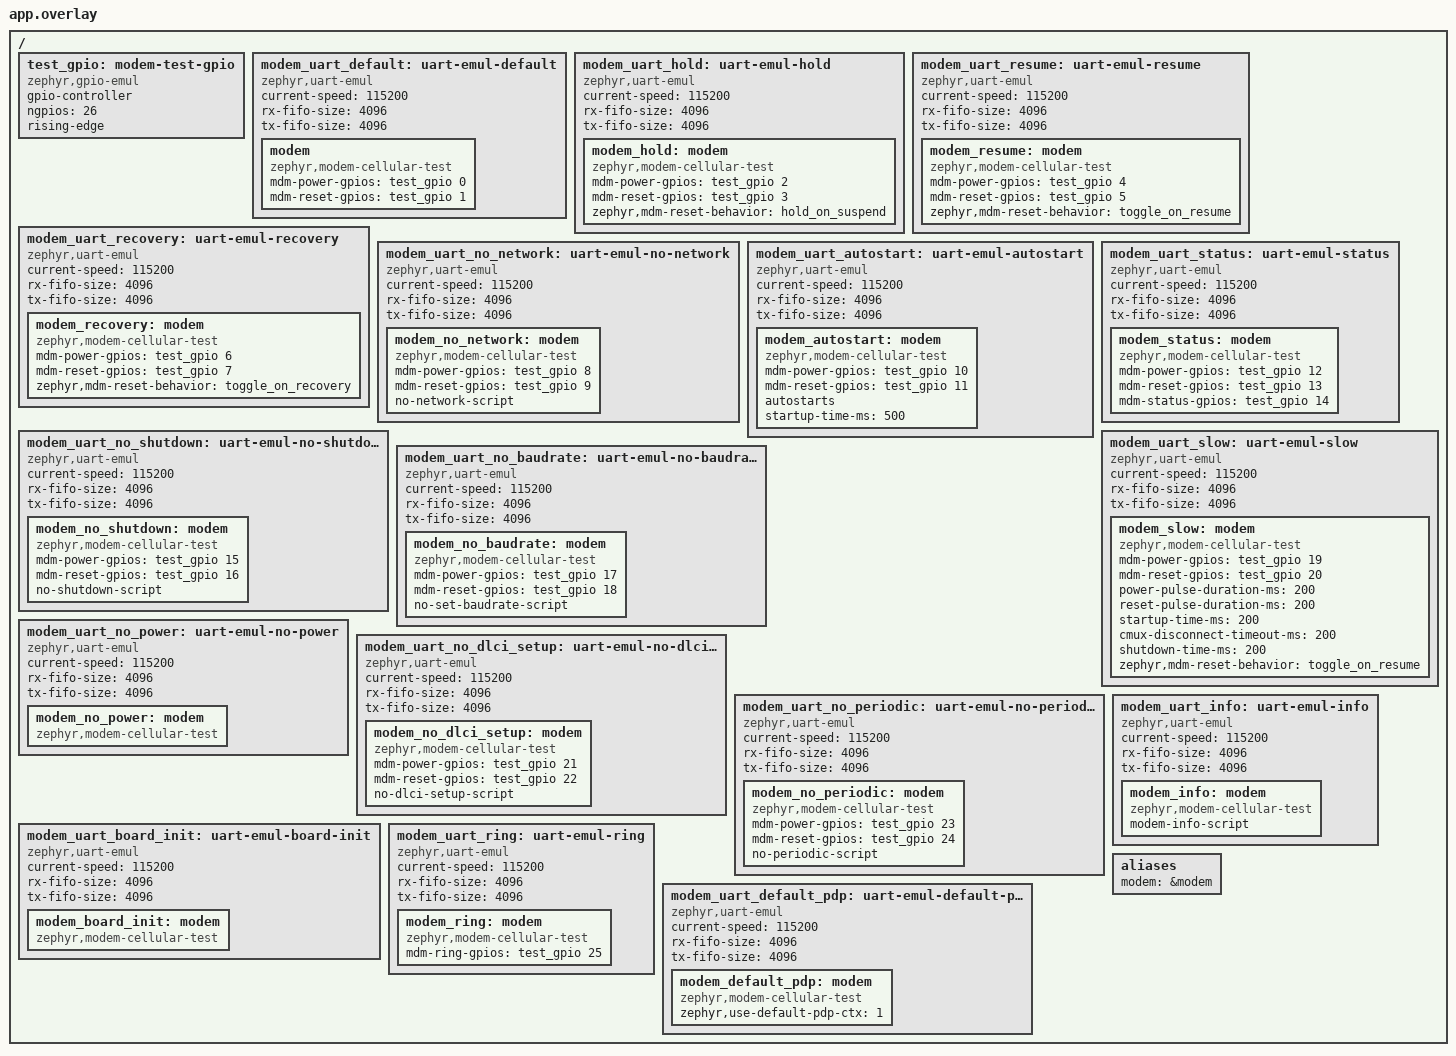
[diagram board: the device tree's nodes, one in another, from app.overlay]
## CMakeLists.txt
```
# Copyright (c) 2026 Embeint Inc
# SPDX-License-Identifier: Apache-2.0

cmake_minimum_required(VERSION 3.28.0)
find_package(Zephyr REQUIRED HINTS $ENV{ZEPHYR_BASE})
project(modem_cellular_state_machine_test)

target_sources(app PRIVATE
  driver/modem_cellular_test.c
  src/common/stubs.c
  src/common/test_helpers.c
)
target_include_directories(app PRIVATE
  driver
  src/common
  ${ZEPHYR_BASE}/subsys/modem
)

# On-demand connect rejects modems with a network script, so it runs on its own devicetree
if(CONFIG_MODEM_CELLULAR_ON_DEMAND_CONNECT)
  target_sources(app PRIVATE
    src/on_demand.c
  )
else()
  target_sources(app PRIVATE
    src/api.c
    src/board_init.c
    src/gpio.c
    src/main.c
    src/modem_info.c
    src/network_status.c
    src/periodic.c
    src/ppp_dead.c
    src/ring.c
    src/script_errors.c
    src/signal.c
    src/suspend.c
    src/unsolicited.c
  )
endif()
```

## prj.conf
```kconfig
# Copyright (c) 2026 Embeint Inc
# SPDX-License-Identifier: Apache-2.0

CONFIG_ZTEST=y

CONFIG_SERIAL=y
CONFIG_EMUL=y
CONFIG_UART_EMUL=y
CONFIG_GPIO=y

CONFIG_MODEM=y
CONFIG_MODEM_MODULES=y
CONFIG_MODEM_CELLULAR=y
CONFIG_MODEM_CELLULAR_HW_DEPENDENCIES=n
CONFIG_MODEM_CHAT=y
CONFIG_MODEM_PIPELINK=y

CONFIG_NETWORKING=y
CONFIG_NET_L2_PPP=y
CONFIG_NET_MGMT=y
CONFIG_NET_MGMT_EVENT=y
CONFIG_PM_DEVICE=y

CONFIG_ETH_NATIVE_TAP=n

CONFIG_LOG=y
CONFIG_LOG_MODE_IMMEDIATE=y
CONFIG_MODEM_LOG_LEVEL_INF=y

CONFIG_MODEM_CELLULAR_APN=""
# Differs from the UARTs' current-speed so baudrate changes are observable
CONFIG_MODEM_CELLULAR_NEW_BAUDRATE=921600
CONFIG_MODEM_CELLULAR_NEW_BAUDRATE_DELAY=1
CONFIG_MODEM_CELLULAR_RESET_POWER_ON_DELAY_MS=100
CONFIG_MODEM_CELLULAR_RECOVERY_BACKOFF_MS=100
CONFIG_MODEM_CELLULAR_MAX_RECOVERIES=3
CONFIG_MODEM_CELLULAR_PERIODIC_SCRIPT_MS=500

CONFIG_MAIN_STACK_SIZE=4096
CONFIG_SYSTEM_WORKQUEUE_STACK_SIZE=4096
CONFIG_ZTEST_STACK_SIZE=4096
```

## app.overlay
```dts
/*
 * Copyright (c) 2026 Embeint Inc
 *
 * SPDX-License-Identifier: Apache-2.0
 */

/ {
	test_gpio: modem-test-gpio {
		compatible = "zephyr,gpio-emul";
		gpio-controller;
		#gpio-cells = <2>;
		ngpios = <26>;
		/* The ring indicator interrupts on its rising edge */
		rising-edge;
		status = "okay";
	};

	modem_uart_default: uart-emul-default {
		compatible = "zephyr,uart-emul";
		current-speed = <115200>;
		rx-fifo-size = <4096>;
		tx-fifo-size = <4096>;
		status = "okay";

		modem: modem {
			compatible = "zephyr,modem-cellular-test";
			mdm-power-gpios = <&test_gpio 0 0>;
			mdm-reset-gpios = <&test_gpio 1 0>;
			status = "okay";
		};
	};

	modem_uart_hold: uart-emul-hold {
		compatible = "zephyr,uart-emul";
		current-speed = <115200>;
		rx-fifo-size = <4096>;
		tx-fifo-size = <4096>;
		status = "okay";

		modem_hold: modem {
			compatible = "zephyr,modem-cellular-test";
			mdm-power-gpios = <&test_gpio 2 0>;
			mdm-reset-gpios = <&test_gpio 3 0>;
			zephyr,mdm-reset-behavior = "hold_on_suspend";
			status = "okay";
		};
	};

	modem_uart_resume: uart-emul-resume {
		compatible = "zephyr,uart-emul";
		current-speed = <115200>;
		rx-fifo-size = <4096>;
		tx-fifo-size = <4096>;
		status = "okay";

		modem_resume: modem {
			compatible = "zephyr,modem-cellular-test";
			mdm-power-gpios = <&test_gpio 4 0>;
			mdm-reset-gpios = <&test_gpio 5 0>;
			zephyr,mdm-reset-behavior = "toggle_on_resume";
			status = "okay";
		};
	};

	modem_uart_recovery: uart-emul-recovery {
		compatible = "zephyr,uart-emul";
		current-speed = <115200>;
		rx-fifo-size = <4096>;
		tx-fifo-size = <4096>;
		status = "okay";

		modem_recovery: modem {
			compatible = "zephyr,modem-cellular-test";
			mdm-power-gpios = <&test_gpio 6 0>;
			mdm-reset-gpios = <&test_gpio 7 0>;
			zephyr,mdm-reset-behavior = "toggle_on_recovery";
			status = "okay";
		};
	};

	modem_uart_no_network: uart-emul-no-network {
		compatible = "zephyr,uart-emul";
		current-speed = <115200>;
		rx-fifo-size = <4096>;
		tx-fifo-size = <4096>;
		status = "okay";

		modem_no_network: modem {
			compatible = "zephyr,modem-cellular-test";
			mdm-power-gpios = <&test_gpio 8 0>;
			mdm-reset-gpios = <&test_gpio 9 0>;
			no-network-script;
			status = "okay";
		};
	};

	modem_uart_autostart: uart-emul-autostart {
		compatible = "zephyr,uart-emul";
		current-speed = <115200>;
		rx-fifo-size = <4096>;
		tx-fifo-size = <4096>;
		status = "okay";

		modem_autostart: modem {
			compatible = "zephyr,modem-cellular-test";
			mdm-power-gpios = <&test_gpio 10 0>;
			mdm-reset-gpios = <&test_gpio 11 0>;
			autostarts;
			startup-time-ms = <500>;
			status = "okay";
		};
	};

	modem_uart_status: uart-emul-status {
		compatible = "zephyr,uart-emul";
		current-speed = <115200>;
		rx-fifo-size = <4096>;
		tx-fifo-size = <4096>;
		status = "okay";

		modem_status: modem {
			compatible = "zephyr,modem-cellular-test";
			mdm-power-gpios = <&test_gpio 12 0>;
			mdm-reset-gpios = <&test_gpio 13 0>;
			mdm-status-gpios = <&test_gpio 14 0>;
			status = "okay";
		};
	};

	modem_uart_no_shutdown: uart-emul-no-shutdown {
		compatible = "zephyr,uart-emul";
		current-speed = <115200>;
		rx-fifo-size = <4096>;
		tx-fifo-size = <4096>;
		status = "okay";

		modem_no_shutdown: modem {
			compatible = "zephyr,modem-cellular-test";
			mdm-power-gpios = <&test_gpio 15 0>;
			mdm-reset-gpios = <&test_gpio 16 0>;
			no-shutdown-script;
			status = "okay";
		};
	};

	modem_uart_no_baudrate: uart-emul-no-baudrate {
		compatible = "zephyr,uart-emul";
		current-speed = <115200>;
		rx-fifo-size = <4096>;
		tx-fifo-size = <4096>;
		status = "okay";

		modem_no_baudrate: modem {
			compatible = "zephyr,modem-cellular-test";
			mdm-power-gpios = <&test_gpio 17 0>;
			mdm-reset-gpios = <&test_gpio 18 0>;
			no-set-baudrate-script;
			status = "okay";
		};
	};

	modem_uart_slow: uart-emul-slow {
		compatible = "zephyr,uart-emul";
		current-speed = <115200>;
		rx-fifo-size = <4096>;
		tx-fifo-size = <4096>;
		status = "okay";

		/* Every timed state lasts long enough for a test to act within it */
		modem_slow: modem {
			compatible = "zephyr,modem-cellular-test";
			mdm-power-gpios = <&test_gpio 19 0>;
			mdm-reset-gpios = <&test_gpio 20 0>;
			power-pulse-duration-ms = <200>;
			reset-pulse-duration-ms = <200>;
			startup-time-ms = <200>;
			cmux-disconnect-timeout-ms = <200>;
			shutdown-time-ms = <200>;
			zephyr,mdm-reset-behavior = "toggle_on_resume";
			status = "okay";
		};
	};

	modem_uart_no_power: uart-emul-no-power {
		compatible = "zephyr,uart-emul";
		current-speed = <115200>;
		rx-fifo-size = <4096>;
		tx-fifo-size = <4096>;
		status = "okay";

		modem_no_power: modem {
			compatible = "zephyr,modem-cellular-test";
			status = "okay";
		};
	};

	modem_uart_no_dlci_setup: uart-emul-no-dlci-setup {
		compatible = "zephyr,uart-emul";
		current-speed = <115200>;
		rx-fifo-size = <4096>;
		tx-fifo-size = <4096>;
		status = "okay";

		modem_no_dlci_setup: modem {
			compatible = "zephyr,modem-cellular-test";
			mdm-power-gpios = <&test_gpio 21 0>;
			mdm-reset-gpios = <&test_gpio 22 0>;
			no-dlci-setup-script;
			status = "okay";
		};
	};

	modem_uart_no_periodic: uart-emul-no-periodic {
		compatible = "zephyr,uart-emul";
		current-speed = <115200>;
		rx-fifo-size = <4096>;
		tx-fifo-size = <4096>;
		status = "okay";

		modem_no_periodic: modem {
			compatible = "zephyr,modem-cellular-test";
			mdm-power-gpios = <&test_gpio 23 0>;
			mdm-reset-gpios = <&test_gpio 24 0>;
			no-periodic-script;
			status = "okay";
		};
	};

	modem_uart_info: uart-emul-info {
		compatible = "zephyr,uart-emul";
		current-speed = <115200>;
		rx-fifo-size = <4096>;
		tx-fifo-size = <4096>;
		status = "okay";

		modem_info: modem {
			compatible = "zephyr,modem-cellular-test";
			modem-info-script;
			status = "okay";
		};
	};

	modem_uart_board_init: uart-emul-board-init {
		compatible = "zephyr,uart-emul";
		current-speed = <115200>;
		rx-fifo-size = <4096>;
		tx-fifo-size = <4096>;
		status = "okay";

		/* The only instance with a board init script */
		modem_board_init: modem {
			compatible = "zephyr,modem-cellular-test";
			status = "okay";
		};
	};

	modem_uart_ring: uart-emul-ring {
		compatible = "zephyr,uart-emul";
		current-speed = <115200>;
		rx-fifo-size = <4096>;
		tx-fifo-size = <4096>;
		status = "okay";

		modem_ring: modem {
			compatible = "zephyr,modem-cellular-test";
			mdm-ring-gpios = <&test_gpio 25 0>;
			status = "okay";
		};
	};

	modem_uart_default_pdp: uart-emul-default-pdp {
		compatible = "zephyr,uart-emul";
		current-speed = <115200>;
		rx-fifo-size = <4096>;
		tx-fifo-size = <4096>;
		status = "okay";

		/* The modem activates the default context (cid 0) itself, no APN is configured */
		modem_default_pdp: modem {
			compatible = "zephyr,modem-cellular-test";
			zephyr,use-default-pdp-ctx = <1>;
			status = "okay";
		};
	};

	aliases {
		modem = &modem;
	};
};
```

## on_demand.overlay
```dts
/*
 * Copyright (c) 2026 Embeint Inc
 *
 * SPDX-License-Identifier: Apache-2.0
 */

/ {
	test_gpio: modem-test-gpio {
		compatible = "zephyr,gpio-emul";
		gpio-controller;
		#gpio-cells = <2>;
		ngpios = <3>;
		/* The ring indicator interrupts on its rising edge */
		rising-edge;
		status = "okay";
	};

	modem_uart_on_demand: uart-emul-on-demand {
		compatible = "zephyr,uart-emul";
		current-speed = <115200>;
		rx-fifo-size = <4096>;
		tx-fifo-size = <4096>;
		status = "okay";

		/* On-demand connect requires a modem without a network script */
		modem_on_demand: modem {
			compatible = "zephyr,modem-cellular-test";
			mdm-power-gpios = <&test_gpio 0 0>;
			mdm-reset-gpios = <&test_gpio 1 0>;
			mdm-ring-gpios = <&test_gpio 2 0>;
			no-network-script;
			status = "okay";
		};
	};
};
```

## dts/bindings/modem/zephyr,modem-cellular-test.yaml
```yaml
# Copyright (c) 2026 Embeint Inc
# SPDX-License-Identifier: Apache-2.0

description: Zephyr test cellular modem

compatible: "zephyr,modem-cellular-test"

include: zephyr,cellular-modem-device.yaml

properties:
  no-set-baudrate-script:
    type: boolean
    description: Omit the optional UART baud-rate configuration script

  no-network-script:
    type: boolean
    description: Omit the optional network registration script

  no-periodic-script:
    type: boolean
    description: Omit the optional periodic status script

  no-shutdown-script:
    type: boolean
    description: Omit the optional modem shutdown script

  no-dlci-setup-script:
    type: boolean
    description: Omit the optional DLCI setup script

  modem-info-script:
    type: boolean
    description: Query every modem info string as part of the init script

  startup-time-ms:
    type: int
    default: 1
    description: Time to wait for the modem ready indication after power on

  power-pulse-duration-ms:
    type: int
    default: 1
    description: Duration of the power key pulse

  reset-pulse-duration-ms:
    type: int
    default: 1
    description: Duration of the reset pulse

  cmux-disconnect-timeout-ms:
    type: int
    default: 1
    description: Time to wait for the modem to return to AT mode after CMUX disconnects

  shutdown-time-ms:
    type: int
    default: 1
    description: Time to wait for the modem to power off
```

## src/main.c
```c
/*
 * Copyright (c) 2026 Embeint Inc
 *
 * SPDX-License-Identifier: Apache-2.0
 */

#include "test_helpers.h"

#include <zephyr/device.h>
#include <zephyr/drivers/modem/modem_cellular.h>
#include <modem_cellular_test.h>
#include <zephyr/modem/pipe.h>
#include <zephyr/modem/pipelink.h>
#include <zephyr/ztest.h>

#include <string.h>

BUILD_ASSERT(IS_ENABLED(CONFIG_MODEM_CHAT));
BUILD_ASSERT(IS_ENABLED(CONFIG_MODEM_PIPELINK));
BUILD_ASSERT(!IS_ENABLED(CONFIG_MODEM_CMUX));
BUILD_ASSERT(!IS_ENABLED(CONFIG_MODEM_PPP));
BUILD_ASSERT(!IS_ENABLED(CONFIG_MODEM_BACKEND_UART));

static const struct device *const modem = DEVICE_DT_GET(DT_ALIAS(modem));
static const struct device *const modem_no_network = DEVICE_DT_GET(DT_NODELABEL(modem_no_network));
static const struct device *const modem_no_baudrate =
	DEVICE_DT_GET(DT_NODELABEL(modem_no_baudrate));
static const struct device *const modem_no_dlci_setup =
	DEVICE_DT_GET(DT_NODELABEL(modem_no_dlci_setup));

MODEM_PIPELINK_DT_DECLARE(DT_ALIAS(modem), user_pipe_0);
MODEM_PIPELINK_DT_DECLARE(DT_ALIAS(modem), user_pipe_1);

/* Answer the first periodic script and check the driver stays registered */
static void run_periodic_script(const struct device *dev)
{
	expect_line(TEST_BACKEND_PIPE_DLCI1, MODEM_CELLULAR_TEST_PERIODIC_CMD);
	ok(TEST_BACKEND_PIPE_DLCI1);
	expect_state(dev, TEST_BACKEND_STATE_LINK_UP);
}

ZTEST(modem_cellular_state_machine, test_boot_with_network_script)
{
	modem_restart(modem);
	advance_to(modem, BOOT_LINK_UP);
	zassert_equal(CONFIG_MODEM_CELLULAR_NEW_BAUDRATE, uart_baudrate(modem),
		      "UART baudrate was not switched");

	run_periodic_script(modem);
	suspend_and_shutdown(modem);

	/* The modem powers up at its default baudrate, so the UART must be restored first */
	zassert_ok(modem_cellular_pm_action(modem, PM_DEVICE_ACTION_RESUME), "resume failed");
	expect_line(TEST_BACKEND_PIPE_UART, MODEM_CELLULAR_TEST_SET_BAUDRATE_CMD);
	zassert_equal(modem_power_up_baudrate(modem), uart_baudrate(modem),
		      "UART baudrate was not restored on power up");
	ok(TEST_BACKEND_PIPE_UART);

	expect_line(TEST_BACKEND_PIPE_UART, MODEM_CELLULAR_TEST_INIT_CMD);
	zassert_equal(CONFIG_MODEM_CELLULAR_NEW_BAUDRATE, uart_baudrate(modem),
		      "UART baudrate was not switched");
}

ZTEST(modem_cellular_state_machine, test_boot_without_network_script)
{
	modem_restart(modem_no_network);

	/* Dials straight after the APN script, then waits for registration */
	advance_to(modem_no_network, BOOT_LINK_UP);
	run_periodic_script(modem_no_network);
	suspend_and_shutdown(modem_no_network);
}

ZTEST(modem_cellular_state_machine, test_boot_without_set_baudrate_script)
{
	const uint32_t original = uart_baudrate(modem_no_baudrate);

	modem_restart(modem_no_baudrate);

	/* Boot goes straight to the init script and leaves the UART untouched */
	advance_to(modem_no_baudrate, BOOT_LINK_UP);
	zassert_equal(original, uart_baudrate(modem_no_baudrate), "UART baudrate changed");

	run_periodic_script(modem_no_baudrate);
	suspend_and_shutdown(modem_no_baudrate);
	zassert_equal(original, uart_baudrate(modem_no_baudrate), "UART baudrate changed");
}

ZTEST(modem_cellular_state_machine, test_boot_without_dlci_setup_script)
{
	modem_restart(modem_no_dlci_setup);

	/* The APN command is the first line once the CMUX is up */
	advance_to(modem_no_dlci_setup, BOOT_LINK_UP);
	run_periodic_script(modem_no_dlci_setup);
	suspend_and_shutdown(modem_no_dlci_setup);
}

/* PPP may never report the link dead, so losing registration must not park the driver */
ZTEST(modem_cellular_state_machine, test_deregistration_without_ppp_dead)
{
	modem_restart(modem);
	advance_to(modem, BOOT_DEREGISTERED);

	/* PPP is released once the wait for it times out */
	expect_state(modem, TEST_BACKEND_STATE_CMUX);
	registered(TEST_BACKEND_PIPE_DLCI1);
	expect_line(TEST_BACKEND_PIPE_DLCI2, MODEM_CELLULAR_TEST_DIAL_CMD);
	ok(TEST_BACKEND_PIPE_DLCI2);
	expect_state(modem, TEST_BACKEND_STATE_LINK_UP);
}

/* User pipes are connected while the CMUX is up, each carrying its own DLCI */
ZTEST(modem_cellular_state_machine, test_user_pipes)
{
	static const char cmd[] = "AT+USER\r";
	const struct {
		struct modem_pipelink *link;
		enum test_backend_pipe_id pipe;
	} user_pipes[] = {
		{MODEM_PIPELINK_DT_GET(DT_ALIAS(modem), user_pipe_0), TEST_BACKEND_PIPE_USER3},
		{MODEM_PIPELINK_DT_GET(DT_ALIAS(modem), user_pipe_1), TEST_BACKEND_PIPE_USER4},
	};

	modem_restart(modem);
	advance_to(modem, BOOT_CMUX_PENDING);
	for (size_t i = 0; i < ARRAY_SIZE(user_pipes); i++) {
		zassert_false(modem_pipelink_is_connected(user_pipes[i].link),
			      "user pipe %zu connected before the CMUX", i);
	}

	test_backend_cmux_connect_finish(true);
	expect_line(TEST_BACKEND_PIPE_DLCI1, MODEM_CELLULAR_TEST_DLCI_SETUP_CMD);
	for (size_t i = 0; i < ARRAY_SIZE(user_pipes); i++) {
		struct modem_pipe *pipe = modem_pipelink_get_pipe(user_pipes[i].link);

		zassert_true(modem_pipelink_is_connected(user_pipes[i].link),
			     "user pipe %zu not connected", i);
		zassert_ok(modem_pipe_open(pipe, K_SECONDS(2)));
		zassert_true(test_backend_pipe_is_open(user_pipes[i].pipe));
		zassert_equal(strlen(cmd),
			      modem_pipe_transmit(pipe, (const uint8_t *)cmd, strlen(cmd)));
		expect_line(user_pipes[i].pipe, "AT+USER");
	}

	ok(TEST_BACKEND_PIPE_DLCI1);
	suspend_and_shutdown(modem);
	for (size_t i = 0; i < ARRAY_SIZE(user_pipes); i++) {
		zassert_false(modem_pipelink_is_connected(user_pipes[i].link),
			      "user pipe %zu still connected after suspend", i);
	}
}

/* Halting the driver disconnects the user pipes, as the idle state does */
ZTEST(modem_cellular_state_machine, test_user_pipes_halt)
{
	struct modem_pipelink *const links[] = {
		MODEM_PIPELINK_DT_GET(DT_ALIAS(modem), user_pipe_0),
		MODEM_PIPELINK_DT_GET(DT_ALIAS(modem), user_pipe_1),
	};

	modem_restart(modem);
	advance_to(modem, BOOT_DLCI1_SETUP);
	for (size_t i = 0; i < ARRAY_SIZE(links); i++) {
		zassert_true(modem_pipelink_is_connected(links[i]), "user pipe %zu not connected",
			     i);
	}

	modem_cellular_ztest_halt(modem);
	for (size_t i = 0; i < ARRAY_SIZE(links); i++) {
		zassert_false(modem_pipelink_is_connected(links[i]),
			      "user pipe %zu still connected after halt", i);
	}
}

ZTEST_SUITE(modem_cellular_state_machine, NULL, modem_test_setup, modem_test_before,
	    modem_test_after, NULL);
```

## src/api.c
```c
/*
 * Copyright (c) 2026 Embeint Inc
 *
 * SPDX-License-Identifier: Apache-2.0
 */

#include "test_helpers.h"

#include <zephyr/device.h>
#include <zephyr/drivers/cellular.h>
#include <zephyr/drivers/modem/modem_cellular.h>
#include <zephyr/ztest.h>

#include <stdio.h>
#include <string.h>

static const struct device *const modem = DEVICE_DT_GET(DT_ALIAS(modem));

/* Out of range for each enumeration */
#define INVALID_SIGNAL_TYPE ((enum cellular_signal_type)99)
#define INVALID_INFO_TYPE   ((enum cellular_modem_info_type)99)
#define INVALID_ACCESS_TECH ((enum cellular_access_technology)99)

/* An unknown signal type is rejected without querying the modem */
ZTEST(modem_cellular_api, test_get_signal)
{
	int16_t value = 0;

	modem_restart(modem);
	advance_to(modem, BOOT_LINK_UP);

	zassert_equal(-ENOTSUP, cellular_get_signal(modem, INVALID_SIGNAL_TYPE, &value));
	zassert_equal(0, value, "value written");
	expect_no_line(K_MSEC(100));
}

ZTEST(modem_cellular_api, test_get_modem_info)
{
	char buf[MODEM_CELLULAR_DATA_IMEI_LEN];

	modem_restart(modem);
	advance_to(modem, BOOT_LINK_UP);

	zassert_equal(-ENODATA, cellular_get_modem_info(modem, INVALID_INFO_TYPE, buf,
							 sizeof(buf)));
	zassert_equal(-EINVAL, cellular_get_modem_info(modem, CELLULAR_MODEM_INFO_IMEI, buf, 0));
	zassert_equal(-EINVAL, cellular_get_modem_info(modem, CELLULAR_MODEM_INFO_IMEI, buf, 1));
}

ZTEST(modem_cellular_api, test_get_registration_status)
{
	enum cellular_registration_status status;

	modem_restart(modem);
	advance_to(modem, BOOT_LINK_UP);

	zassert_equal(-ENODATA, cellular_get_registration_status(
					modem, CELLULAR_ACCESS_TECHNOLOGY_UNKNOWN, &status));
	zassert_equal(-ENODATA, cellular_get_registration_status(modem, INVALID_ACCESS_TECH,
								  &status));
}

/* Missing, empty and oversized APNs are rejected and leave the driver waiting for one */
ZTEST(modem_cellular_api, test_set_apn_invalid)
{
	/* One character more than the driver stores, with its terminator */
	char apn[MODEM_CELLULAR_DATA_APN_LEN + 1];
	char cmd[sizeof(apn) + 32];

	modem_restart(modem);
	advance_to(modem, BOOT_AWAIT_APN);

	memset(apn, 'a', MODEM_CELLULAR_DATA_APN_LEN);
	apn[MODEM_CELLULAR_DATA_APN_LEN] = '\0';
	zassert_equal(-EINVAL, cellular_set_apn(modem, NULL));
	zassert_equal(-EINVAL, cellular_set_apn(modem, ""));
	zassert_equal(-EINVAL, cellular_set_apn(modem, apn), "APN of %zu accepted", strlen(apn));
	expect_no_line(K_MSEC(100));

	/* The longest that fits is configured */
	apn[MODEM_CELLULAR_DATA_APN_LEN - 1] = '\0';
	zassert_ok(cellular_set_apn(modem, apn));
	snprintf(cmd, sizeof(cmd), "AT+CGDCONT=1,\"IP\",\"%s\"", apn);
	expect_line(TEST_BACKEND_PIPE_DLCI1, cmd);
}

/* Once configured, the APN cannot be set again or changed while connected */
ZTEST(modem_cellular_api, test_set_apn_configured)
{
	modem_restart(modem);
	advance_to(modem, BOOT_LINK_UP);

	zassert_equal(-EALREADY, cellular_set_apn(modem, TEST_APN));
	zassert_equal(-EBUSY, cellular_set_apn(modem, "other"));
	expect_no_line(K_MSEC(100));
}

ZTEST_SUITE(modem_cellular_api, NULL, modem_test_setup, modem_test_before, modem_test_after, NULL);
```

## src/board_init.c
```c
/*
 * Copyright (c) 2026 Embeint Inc
 *
 * SPDX-License-Identifier: Apache-2.0
 */

#include "test_helpers.h"

#include <zephyr/device.h>
#include <zephyr/drivers/cellular.h>
#include <zephyr/drivers/modem/modem_cellular.h>
#include <modem_cellular_test.h>
#include <zephyr/modem/chat.h>
#include <zephyr/ztest.h>

#define BOARD_INIT_CMD_1 "AT+BOARDINIT=1"
#define BOARD_INIT_CMD_2 "AT+BOARDINIT=2"

static const struct device *const modem_board_init =
	DEVICE_DT_GET(DT_NODELABEL(modem_board_init));

MODEM_CHAT_MATCH_DEFINE(board_init_ok_match, "OK", "", NULL);
MODEM_CHAT_MATCHES_DEFINE(board_init_abort_matches, MODEM_CHAT_MATCH("ERROR", "", NULL));
MODEM_CHAT_SCRIPT_CMDS_DEFINE(board_init_cmds,
			      MODEM_CHAT_SCRIPT_CMD_RESP(BOARD_INIT_CMD_1, board_init_ok_match),
			      MODEM_CHAT_SCRIPT_CMD_RESP(BOARD_INIT_CMD_2, board_init_ok_match));
/* The driver replaces the callback with its own */
MODEM_CHAT_SCRIPT_DEFINE(board_init_script, board_init_cmds, board_init_abort_matches, NULL, 1);

MODEM_CELLULAR_BOARD_INIT_DEFINE(DT_NODELABEL(modem_board_init), &board_init_script);

/* Boot until the board init script is about to start, after the DLCI setup */
static void boot_to_board_init(void)
{
	modem_restart(modem_board_init);
	advance_to(modem_board_init, BOOT_DLCI2_SETUP);
	ok(TEST_BACKEND_PIPE_DLCI2);
}

/* Answer the whole board init script */
static void run_board_init(void)
{
	expect_line(TEST_BACKEND_PIPE_DLCI1, BOARD_INIT_CMD_1);
	ok(TEST_BACKEND_PIPE_DLCI1);
	expect_line(TEST_BACKEND_PIPE_DLCI1, BOARD_INIT_CMD_2);
	ok(TEST_BACKEND_PIPE_DLCI1);
}

/* With the script done, the driver moves on to the APN */
static void expect_apn(void)
{
	expect_read(TEST_BACKEND_PIPE_DLCI1);
	expect_no_line(K_MSEC(100));
	zassert_ok(cellular_set_apn(modem_board_init, TEST_APN));
	expect_line(TEST_BACKEND_PIPE_DLCI1, TEST_APN_CMD);
}

/* The script runs on DLCI1 once the DLCI setup is done, before the APN is configured */
ZTEST(modem_cellular_board_init, test_runs_before_apn)
{
	boot_to_board_init();
	run_board_init();
	expect_apn();
}

/* A failed script is run again from the start after the periodic interval */
ZTEST(modem_cellular_board_init, test_retried)
{
	int64_t start;

	boot_to_board_init();
	expect_line(TEST_BACKEND_PIPE_DLCI1, BOARD_INIT_CMD_1);
	ok(TEST_BACKEND_PIPE_DLCI1);
	expect_line(TEST_BACKEND_PIPE_DLCI1, BOARD_INIT_CMD_2);

	start = k_uptime_get();
	respond_error(TEST_BACKEND_PIPE_DLCI1);
	expect_no_line(K_MSEC(CONFIG_MODEM_CELLULAR_PERIODIC_SCRIPT_MS / 2));
	run_board_init();
	zassert_true(k_uptime_delta(&start) >= CONFIG_MODEM_CELLULAR_PERIODIC_SCRIPT_MS,
		     "retried before the periodic interval");
	expect_apn();
}

/* Spending the failure budget powers the modem down */
ZTEST(modem_cellular_board_init, test_failures_shut_down)
{
	boot_to_board_init();
	for (int i = 0; i < CONFIG_MODEM_CELLULAR_MAX_SCRIPT_FAILURES; i++) {
		expect_line(TEST_BACKEND_PIPE_DLCI1, BOARD_INIT_CMD_1);
		respond_error(TEST_BACKEND_PIPE_DLCI1);
	}

	expect_line(TEST_BACKEND_PIPE_UART, MODEM_CELLULAR_TEST_SHUTDOWN_CMD);
	ok(TEST_BACKEND_PIPE_UART);
	expect_state(modem_board_init, TEST_BACKEND_STATE_OFF);
	expect_no_line(K_MSEC(CONFIG_MODEM_CELLULAR_PERIODIC_SCRIPT_MS * 2));
}

ZTEST(modem_cellular_board_init, test_suspend)
{
	boot_to_board_init();
	expect_line(TEST_BACKEND_PIPE_DLCI1, BOARD_INIT_CMD_1);
	suspend_and_shutdown(modem_board_init);
}

ZTEST_SUITE(modem_cellular_board_init, NULL, modem_test_setup, modem_test_before,
	    modem_test_after, NULL);
```

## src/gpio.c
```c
/*
 * Copyright (c) 2026 Embeint Inc
 *
 * SPDX-License-Identifier: Apache-2.0
 */

#include "test_helpers.h"

#include <zephyr/device.h>
#include <zephyr/drivers/gpio/gpio_emul.h>
#include <zephyr/drivers/modem/modem_cellular.h>
#include <modem_cellular_test.h>
#include <zephyr/ztest.h>

#define AUTOSTART_STARTUP_TIME_MS DT_PROP(DT_NODELABEL(modem_autostart), startup_time_ms)

static const struct device *const modem = DEVICE_DT_GET(DT_ALIAS(modem));
static const struct device *const modem_hold = DEVICE_DT_GET(DT_NODELABEL(modem_hold));
static const struct device *const modem_resume = DEVICE_DT_GET(DT_NODELABEL(modem_resume));
static const struct device *const modem_recovery = DEVICE_DT_GET(DT_NODELABEL(modem_recovery));
static const struct device *const modem_autostart =
	DEVICE_DT_GET(DT_NODELABEL(modem_autostart));
static const struct device *const modem_status = DEVICE_DT_GET(DT_NODELABEL(modem_status));
static const struct device *const modem_no_shutdown =
	DEVICE_DT_GET(DT_NODELABEL(modem_no_shutdown));

static const struct gpio_dt_spec status_gpio =
	GPIO_DT_SPEC_GET(DT_NODELABEL(modem_status), mdm_status_gpios);

enum gpio_role {
	GPIO_ROLE_POWER,
	GPIO_ROLE_RESET,
};

/* A level change on a monitored pin, and the state of the link when it happened */
struct gpio_edge {
	enum gpio_role role;
	int value;
	enum test_backend_state state;
};

K_MSGQ_DEFINE(gpio_edges, sizeof(struct gpio_edge), 16, 4);

static struct {
	const struct device *dev;
	struct gpio_callback cb;
	int last[2];
	bool overflow;
} monitor;

static const char *const gpio_role_names[] = {
	[GPIO_ROLE_POWER] = "power",
	[GPIO_ROLE_RESET] = "reset",
};

static void gpio_monitor_record(enum gpio_role role, const struct gpio_dt_spec *spec)
{
	struct gpio_edge edge = {
		.role = role,
		.value = gpio_emul_output_get_dt(spec),
		.state = test_backend_state(monitor.dev),
	};

	if (edge.value == monitor.last[role]) {
		return;
	}
	monitor.last[role] = edge.value;
	/* Runs on the driver's thread, so leave asserting to the test thread */
	if (k_msgq_put(&gpio_edges, &edge, K_NO_WAIT) != 0) {
		monitor.overflow = true;
	}
}

/* The emulated GPIO controller fires callbacks synchronously on output changes, so every
 * level the driver drives is seen, however short the pulse.
 */
static void gpio_monitor_handler(const struct device *port, struct gpio_callback *cb,
				 gpio_port_pins_t pins)
{
	ARG_UNUSED(port);
	ARG_UNUSED(cb);
	ARG_UNUSED(pins);

	gpio_monitor_record(GPIO_ROLE_POWER, test_backend_power_gpio(monitor.dev));
	gpio_monitor_record(GPIO_ROLE_RESET, test_backend_reset_gpio(monitor.dev));
}

static void gpio_monitor_start(const struct device *dev)
{
	const struct gpio_dt_spec *power_gpio = test_backend_power_gpio(dev);
	const struct gpio_dt_spec *reset_gpio = test_backend_reset_gpio(dev);

	/* Start every test from released lines so the first recorded edge is the driver's */
	zassert_ok(gpio_pin_configure_dt(power_gpio, GPIO_OUTPUT_INACTIVE));
	zassert_ok(gpio_pin_configure_dt(reset_gpio, GPIO_OUTPUT_INACTIVE));

	monitor.dev = dev;
	monitor.last[GPIO_ROLE_POWER] = 0;
	monitor.last[GPIO_ROLE_RESET] = 0;
	monitor.overflow = false;
	k_msgq_purge(&gpio_edges);

	gpio_init_callback(&monitor.cb, gpio_monitor_handler,
			   BIT(power_gpio->pin) | BIT(reset_gpio->pin));
	zassert_ok(gpio_add_callback_dt(reset_gpio, &monitor.cb));
}

static void gpio_monitor_stop(void)
{
	if (monitor.dev == NULL) {
		return;
	}

	(void)gpio_remove_callback_dt(test_backend_reset_gpio(monitor.dev), &monitor.cb);
	monitor.dev = NULL;
}

/* Wait for the next edge, which must be @p role going to @p value in @p state */
static void expect_edge(enum gpio_role role, int value, enum test_backend_state state)
{
	struct gpio_edge edge;

	zassert_false(monitor.overflow, "GPIO edge queue overflowed");
	zassert_ok(k_msgq_get(&gpio_edges, &edge, K_SECONDS(1)), "timed out waiting for %s=%d",
		   gpio_role_names[role], value);
	zassert_equal(role, edge.role, "%s went to %d, expected %s=%d", gpio_role_names[edge.role],
		      edge.value, gpio_role_names[role], value);
	zassert_equal(value, edge.value, "%s went to %d, expected %d", gpio_role_names[role],
		      edge.value, value);
	zassert_equal(state, edge.state, "%s went to %d in state %d, expected state %d",
		      gpio_role_names[role], value, edge.state, state);
}

/* Expect @p role to be asserted and released again, both in @p state */
static void expect_pulse(enum gpio_role role, enum test_backend_state state)
{
	expect_edge(role, 1, state);
	expect_edge(role, 0, state);
}

/* Assert that neither pin changed since the last expected edge */
static void expect_no_edge(void)
{
	struct gpio_edge edge;

	zassert_false(monitor.overflow, "GPIO edge queue overflowed");
	if (k_msgq_get(&gpio_edges, &edge, K_NO_WAIT) == 0) {
		zassert_unreachable("unexpected %s=%d in state %d", gpio_role_names[edge.role],
				    edge.value, edge.state);
	}
}

static int64_t boot_modem(const struct device *dev)
{
	int64_t start;

	modem_reset_state(dev);
	gpio_monitor_start(dev);

	start = k_uptime_get();
	zassert_ok(modem_cellular_init(dev), "failed to reinitialize %s", dev->name);
	return start;
}

ZTEST(modem_cellular_gpio, test_hold_on_suspend)
{
	boot_modem(modem_hold);

	/* Held through init, released before the power key and the UART */
	expect_edge(GPIO_ROLE_RESET, 1, TEST_BACKEND_STATE_OFF);
	expect_edge(GPIO_ROLE_RESET, 0, TEST_BACKEND_STATE_OFF);
	expect_pulse(GPIO_ROLE_POWER, TEST_BACKEND_STATE_OFF);
	expect_line(TEST_BACKEND_PIPE_UART, MODEM_CELLULAR_TEST_SET_BAUDRATE_CMD);
	expect_no_edge();

	/* Reasserted on suspend */
	zassert_ok(modem_cellular_pm_action(modem_hold, PM_DEVICE_ACTION_SUSPEND),
		   "suspend failed");
	expect_edge(GPIO_ROLE_RESET, 1, TEST_BACKEND_STATE_AT);
	expect_no_edge();

	/* Released again on resume, before the power key and the UART */
	zassert_ok(modem_cellular_pm_action(modem_hold, PM_DEVICE_ACTION_RESUME), "resume failed");
	expect_edge(GPIO_ROLE_RESET, 0, TEST_BACKEND_STATE_OFF);
	expect_pulse(GPIO_ROLE_POWER, TEST_BACKEND_STATE_OFF);
	expect_line(TEST_BACKEND_PIPE_UART, MODEM_CELLULAR_TEST_SET_BAUDRATE_CMD);
	expect_no_edge();
}

ZTEST(modem_cellular_gpio, test_toggle_on_resume)
{
	boot_modem(modem_resume);

	expect_pulse(GPIO_ROLE_RESET, TEST_BACKEND_STATE_OFF);
	expect_pulse(GPIO_ROLE_POWER, TEST_BACKEND_STATE_OFF);
	expect_line(TEST_BACKEND_PIPE_UART, MODEM_CELLULAR_TEST_SET_BAUDRATE_CMD);
	expect_no_edge();

	/* Untouched on suspend */
	zassert_ok(modem_cellular_pm_action(modem_resume, PM_DEVICE_ACTION_SUSPEND),
		   "suspend failed");
	expect_no_edge();

	/* Pulsed again on resume, before the power key and the UART */
	zassert_ok(modem_cellular_pm_action(modem_resume, PM_DEVICE_ACTION_RESUME),
		   "resume failed");
	expect_pulse(GPIO_ROLE_RESET, TEST_BACKEND_STATE_OFF);
	expect_pulse(GPIO_ROLE_POWER, TEST_BACKEND_STATE_OFF);
	expect_line(TEST_BACKEND_PIPE_UART, MODEM_CELLULAR_TEST_SET_BAUDRATE_CMD);
	expect_no_edge();
}

ZTEST(modem_cellular_gpio, test_toggle_on_recovery)
{
	boot_modem(modem_recovery);

	/* Untouched on boot */
	expect_pulse(GPIO_ROLE_POWER, TEST_BACKEND_STATE_OFF);
	expect_line(TEST_BACKEND_PIPE_UART, MODEM_CELLULAR_TEST_SET_BAUDRATE_CMD);
	expect_no_edge();
	ok(TEST_BACKEND_PIPE_UART);

	/* Fail the init script to push the state machine into recovery */
	expect_line(TEST_BACKEND_PIPE_UART, MODEM_CELLULAR_TEST_INIT_CMD);
	respond_error(TEST_BACKEND_PIPE_UART);

	expect_pulse(GPIO_ROLE_RESET, TEST_BACKEND_STATE_AT);
	expect_pulse(GPIO_ROLE_POWER, TEST_BACKEND_STATE_AT);
	expect_line(TEST_BACKEND_PIPE_UART, MODEM_CELLULAR_TEST_SET_BAUDRATE_CMD);
	expect_no_edge();
}

ZTEST(modem_cellular_gpio, test_autostarts_ready_message)
{
	struct test_backend_line line;
	int64_t start = boot_modem(modem_autostart);

	/* No AT commands until the modem reports it is ready */
	zassert_false(test_backend_wait_for_line(&line, K_MSEC(100)), "'%s' sent before ready",
		      line.data);
	zassert_equal(TEST_BACKEND_STATE_AT, test_backend_state(modem_autostart),
		      "boot stopped in state %d", test_backend_state(modem_autostart));
	test_backend_respond(TEST_BACKEND_PIPE_UART, "Ready\r");

	expect_line(TEST_BACKEND_PIPE_UART, MODEM_CELLULAR_TEST_SET_BAUDRATE_CMD);
	zassert_true(k_uptime_delta(&start) < AUTOSTART_STARTUP_TIME_MS,
		     "ready message did not cut the startup wait short");
	expect_no_edge();
}

ZTEST(modem_cellular_gpio, test_autostarts_ready_timeout)
{
	int64_t start = boot_modem(modem_autostart);
	int64_t elapsed;

	/* Without a ready message the full startup time elapses before AT commands */
	expect_line(TEST_BACKEND_PIPE_UART, MODEM_CELLULAR_TEST_SET_BAUDRATE_CMD);
	elapsed = k_uptime_delta(&start);
	zassert_true(elapsed >= AUTOSTART_STARTUP_TIME_MS,
		     "AT commands sent %lld ms after boot, before startup time elapsed",
		     (long long)elapsed);

	/* Autostarting modems go straight to waiting for the modem to come up */
	expect_no_edge();
}

static void set_modem_status(int value)
{
	zassert_ok(gpio_pin_configure_dt(&status_gpio, GPIO_INPUT));
	zassert_ok(gpio_emul_input_set_dt(&status_gpio, value));
}

ZTEST(modem_cellular_gpio, test_status_unpowered)
{
	set_modem_status(0);
	boot_modem(modem_status);

	expect_pulse(GPIO_ROLE_POWER, TEST_BACKEND_STATE_OFF);
	expect_line(TEST_BACKEND_PIPE_UART, MODEM_CELLULAR_TEST_SET_BAUDRATE_CMD);
	expect_no_edge();
}

ZTEST(modem_cellular_gpio, test_status_powered)
{
	set_modem_status(1);
	boot_modem(modem_status);

	/* Pulsing the power key would turn the running modem off */
	advance_to(modem_status, BOOT_DLCI1_SETUP);
	expect_no_edge();
}

ZTEST(modem_cellular_gpio, test_status_powered_unresponsive)
{
	int64_t start;

	set_modem_status(1);
	boot_modem(modem_status);

	advance_to(modem_status, BOOT_INIT);
	expect_no_edge();

	/* The status line was wrong, so power the modem on without the recovery backoff */
	start = k_uptime_get();
	respond_error(TEST_BACKEND_PIPE_UART);
	expect_edge(GPIO_ROLE_POWER, 1, TEST_BACKEND_STATE_AT);
	zassert_true(k_uptime_delta(&start) < CONFIG_MODEM_CELLULAR_RECOVERY_BACKOFF_MS,
		     "recovery was entered");
	expect_edge(GPIO_ROLE_POWER, 0, TEST_BACKEND_STATE_AT);
	expect_line(TEST_BACKEND_PIPE_UART, MODEM_CELLULAR_TEST_SET_BAUDRATE_CMD);
	zassert_equal(modem_power_up_baudrate(modem_status), uart_baudrate(modem_status),
		      "UART baudrate was not restored on power up");
	expect_no_edge();
}

/* A restart that skips the power-on pulse still configures the baudrate from the original */
ZTEST(modem_cellular_gpio, test_status_powered_restart)
{
	set_modem_status(1);
	boot_modem(modem_status);
	advance_to(modem_status, BOOT_LINK_UP);

	/* Spend the periodic script budget to restart the still powered modem */
	for (int i = 0; i < CONFIG_MODEM_CELLULAR_MAX_SCRIPT_FAILURES; i++) {
		expect_line(TEST_BACKEND_PIPE_DLCI1, MODEM_CELLULAR_TEST_PERIODIC_CMD);
		respond_error(TEST_BACKEND_PIPE_DLCI1);
	}
	expect_line(TEST_BACKEND_PIPE_UART, MODEM_CELLULAR_TEST_SET_BAUDRATE_CMD);
	zassert_equal(modem_power_up_baudrate(modem_status), uart_baudrate(modem_status),
		      "baudrate script sent at the new baudrate");
	expect_no_edge();
	ok(TEST_BACKEND_PIPE_UART);

	/* The modem does not respond, so it is powered on at its power up baudrate */
	expect_line(TEST_BACKEND_PIPE_UART, MODEM_CELLULAR_TEST_INIT_CMD);
	respond_error(TEST_BACKEND_PIPE_UART);
	expect_pulse(GPIO_ROLE_POWER, TEST_BACKEND_STATE_AT);
	expect_line(TEST_BACKEND_PIPE_UART, MODEM_CELLULAR_TEST_SET_BAUDRATE_CMD);
	zassert_equal(modem_power_up_baudrate(modem_status), uart_baudrate(modem_status),
		      "UART baudrate was not restored on power up");
	expect_no_edge();
}

/* Suspended during the init script the modem stays powered at the new baudrate, so a resume
 * that finds it still powered keeps that baudrate
 */
ZTEST(modem_cellular_gpio, test_status_powered_resume_keeps_baudrate)
{
	set_modem_status(1);
	boot_modem(modem_status);
	advance_to(modem_status, BOOT_INIT);

	start_suspend(modem_status);
	finish_suspend(modem_status);
	zassert_ok(modem_cellular_pm_action(modem_status, PM_DEVICE_ACTION_RESUME));

	expect_line(TEST_BACKEND_PIPE_UART, MODEM_CELLULAR_TEST_SET_BAUDRATE_CMD);
	zassert_equal(CONFIG_MODEM_CELLULAR_NEW_BAUDRATE, uart_baudrate(modem_status),
		      "baudrate script sent at the original baudrate");
	expect_no_edge();
	ok(TEST_BACKEND_PIPE_UART);

	/* The original baudrate is still restored when the modem is powered on */
	expect_line(TEST_BACKEND_PIPE_UART, MODEM_CELLULAR_TEST_INIT_CMD);
	respond_error(TEST_BACKEND_PIPE_UART);
	expect_pulse(GPIO_ROLE_POWER, TEST_BACKEND_STATE_AT);
	expect_line(TEST_BACKEND_PIPE_UART, MODEM_CELLULAR_TEST_SET_BAUDRATE_CMD);
	zassert_equal(modem_power_up_baudrate(modem_status), uart_baudrate(modem_status),
		      "UART baudrate was not restored on power up");
	expect_no_edge();
}

ZTEST(modem_cellular_gpio, test_shutdown_script_failure)
{
	boot_modem(modem);
	expect_pulse(GPIO_ROLE_POWER, TEST_BACKEND_STATE_OFF);
	advance_to(modem, BOOT_DLCI2_SETUP);

	start_suspend(modem);
	expect_line(TEST_BACKEND_PIPE_UART, MODEM_CELLULAR_TEST_SHUTDOWN_CMD);
	expect_no_edge();

	/* Software shutdown failed, fall back to the power key */
	respond_error(TEST_BACKEND_PIPE_UART);
	expect_pulse(GPIO_ROLE_POWER, TEST_BACKEND_STATE_OFF);
	finish_suspend(modem);
	expect_no_edge();
}

ZTEST(modem_cellular_gpio, test_no_shutdown_script)
{
	boot_modem(modem_no_shutdown);
	expect_pulse(GPIO_ROLE_POWER, TEST_BACKEND_STATE_OFF);
	advance_to(modem_no_shutdown, BOOT_DLCI2_SETUP);

	/* Powered down with the power key alone */
	start_suspend(modem_no_shutdown);
	expect_pulse(GPIO_ROLE_POWER, TEST_BACKEND_STATE_OFF);
	finish_suspend(modem_no_shutdown);
	expect_no_edge();
	expect_no_line(K_MSEC(100));
}

static void gpio_after(void *fixture)
{
	modem_test_after(fixture);
	gpio_monitor_stop();
}

ZTEST_SUITE(modem_cellular_gpio, NULL, modem_test_setup, modem_test_before, gpio_after, NULL);
```

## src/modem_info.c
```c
/*
 * Copyright (c) 2026 Embeint Inc
 *
 * SPDX-License-Identifier: Apache-2.0
 */

#include "test_helpers.h"

#include <zephyr/device.h>
#include <zephyr/drivers/cellular.h>
#include <zephyr/drivers/modem/modem_cellular.h>
#include <modem_cellular_test.h>
#include <zephyr/ztest.h>

#include <string.h>

static const struct device *const modem_info = DEVICE_DT_GET(DT_NODELABEL(modem_info));

/* Each string as left once the init script completes */
static const struct {
	enum cellular_modem_info_type type;
	const char *value;
} expected_info[] = {
	{CELLULAR_MODEM_INFO_IMEI, TEST_IMEI},
	{CELLULAR_MODEM_INFO_SERIAL_NUMBER, TEST_SERIAL_NUMBER},
	{CELLULAR_MODEM_INFO_MODEL_ID, TEST_MODEL_ID},
	{CELLULAR_MODEM_INFO_MANUFACTURER, TEST_MANUFACTURER},
	{CELLULAR_MODEM_INFO_FW_VERSION, TEST_FW_VERSION},
	{CELLULAR_MODEM_INFO_SIM_IMSI, TEST_IMSI},
	{CELLULAR_MODEM_INFO_SIM_ICCID, TEST_ICCID},
};

K_MSGQ_DEFINE(info_events, sizeof(enum cellular_modem_info_type), 16, 4);

static void info_event_handler(const struct device *dev, enum cellular_event event,
			       const void *payload, void *user_data)
{
	const struct cellular_evt_modem_info *info = payload;

	ARG_UNUSED(dev);
	ARG_UNUSED(event);
	ARG_UNUSED(user_data);

	(void)k_msgq_put(&info_events, &info->field, K_NO_WAIT);
}

/* Every string is reported while the init script runs, with an event each time it is set */
ZTEST(modem_cellular_modem_info, test_reported_during_init)
{
	/* The first response sets both the IMEI and the serial number */
	static const enum cellular_modem_info_type expected_events[] = {
		CELLULAR_MODEM_INFO_IMEI,       CELLULAR_MODEM_INFO_SERIAL_NUMBER,
		CELLULAR_MODEM_INFO_IMEI,       CELLULAR_MODEM_INFO_SERIAL_NUMBER,
		CELLULAR_MODEM_INFO_MODEL_ID,   CELLULAR_MODEM_INFO_MANUFACTURER,
		CELLULAR_MODEM_INFO_FW_VERSION, CELLULAR_MODEM_INFO_SIM_IMSI,
		CELLULAR_MODEM_INFO_SIM_ICCID,
	};
	enum cellular_modem_info_type field;
	char buf[MODEM_CELLULAR_DATA_MODEL_ID_LEN];

	k_msgq_purge(&info_events);
	zassert_ok(cellular_set_callback(modem_info, CELLULAR_EVENT_MODEM_INFO_CHANGED,
					 info_event_handler, NULL));

	modem_restart(modem_info);
	advance_to(modem_info, BOOT_DLCI1_SETUP);

	for (size_t i = 0; i < ARRAY_SIZE(expected_events); i++) {
		zassert_ok(k_msgq_get(&info_events, &field, K_NO_WAIT),
			   "no event %zu, for info type %d", i, expected_events[i]);
		zassert_equal(expected_events[i], field, "event %zu for info type %d, expected %d",
			      i, field, expected_events[i]);
	}
	zassert_equal(0, k_msgq_num_used_get(&info_events), "unexpected info events");

	for (size_t i = 0; i < ARRAY_SIZE(expected_info); i++) {
		zassert_ok(cellular_get_modem_info(modem_info, expected_info[i].type, buf,
						   sizeof(buf)));
		zassert_str_equal(expected_info[i].value, buf);
	}

	zassert_ok(cellular_set_callback(modem_info, 0, NULL, NULL));
}

/* Strings are truncated to fit the caller's buffer, which is always terminated */
ZTEST(modem_cellular_modem_info, test_truncated)
{
	char buf[4];

	modem_restart(modem_info);
	advance_to(modem_info, BOOT_DLCI1_SETUP);

	zassert_ok(cellular_get_modem_info(modem_info, CELLULAR_MODEM_INFO_IMEI, buf, sizeof(buf)));
	zassert_str_equal("352", buf);
	zassert_equal(-EINVAL,
		      cellular_get_modem_info(modem_info, CELLULAR_MODEM_INFO_IMEI, buf, 1));
}

/* A bare AT+CGSN answer is taken as both the IMEI and the serial number */
ZTEST(modem_cellular_modem_info, test_imei_as_serial_number)
{
	char buf[MODEM_CELLULAR_DATA_IMEI_LEN];

	modem_restart(modem_info);
	advance_to(modem_info, BOOT_MODEM_INFO);
	test_backend_respond(TEST_BACKEND_PIPE_UART, TEST_IMEI_SN "\r");
	ok(TEST_BACKEND_PIPE_UART);
	expect_line(TEST_BACKEND_PIPE_UART, MODEM_CELLULAR_TEST_IMEI_CMD);

	zassert_ok(cellular_get_modem_info(modem_info, CELLULAR_MODEM_INFO_IMEI, buf, sizeof(buf)));
	zassert_str_equal(TEST_IMEI_SN, buf);
	zassert_ok(cellular_get_modem_info(modem_info, CELLULAR_MODEM_INFO_SERIAL_NUMBER, buf,
					   sizeof(buf)));
	zassert_str_equal(TEST_IMEI_SN, buf);
}

/* An IMEI that is not a quoted 15 digit string is ignored */
ZTEST(modem_cellular_modem_info, test_invalid_imei)
{
	char buf[MODEM_CELLULAR_DATA_IMEI_LEN];

	modem_restart(modem_info);
	advance_to(modem_info, BOOT_MODEM_INFO);
	test_backend_respond(TEST_BACKEND_PIPE_UART, TEST_IMEI_SN "\r");
	ok(TEST_BACKEND_PIPE_UART);

	expect_line(TEST_BACKEND_PIPE_UART, MODEM_CELLULAR_TEST_IMEI_CMD);
	test_backend_respond(TEST_BACKEND_PIPE_UART, "+CGSN: 123\r");
	ok(TEST_BACKEND_PIPE_UART);
	expect_line(TEST_BACKEND_PIPE_UART, MODEM_CELLULAR_TEST_SERIAL_NUMBER_CMD);

	/* Still the IMEI from the previous command */
	zassert_ok(cellular_get_modem_info(modem_info, CELLULAR_MODEM_INFO_IMEI, buf, sizeof(buf)));
	zassert_str_equal(TEST_IMEI_SN, buf);
}

ZTEST_SUITE(modem_cellular_modem_info, NULL, modem_test_setup, modem_test_before, modem_test_after,
	    NULL);
```

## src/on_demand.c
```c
/*
 * Copyright (c) 2026 Embeint Inc
 *
 * SPDX-License-Identifier: Apache-2.0
 */

#include "test_helpers.h"

#include <zephyr/device.h>
#include <zephyr/drivers/cellular.h>
#include <zephyr/drivers/gpio/gpio_emul.h>
#include <zephyr/drivers/modem/modem_cellular.h>
#include <modem_cellular_test.h>
#include <zephyr/net/net_if.h>
#include <zephyr/net/ppp.h>
#include <zephyr/ztest.h>

BUILD_ASSERT(IS_ENABLED(CONFIG_MODEM_CELLULAR_ON_DEMAND_CONNECT));

static const struct device *const modem = DEVICE_DT_GET(DT_NODELABEL(modem_on_demand));

static struct net_if *ppp_iface(void)
{
	struct net_if *iface = net_if_get_first_by_type(&NET_L2_GET_NAME(PPP));

	zassert_not_null(iface, "no PPP interface");
	return iface;
}

/* Boot until the driver parks waiting for the PPP interface to be admitted */
static void park(void)
{
	modem_restart(modem);
	advance_to(modem, BOOT_APN);
	ok(TEST_BACKEND_PIPE_DLCI1);
	expect_read(TEST_BACKEND_PIPE_DLCI1);
	flush_driver_events();
}

/* Parked, the periodic script keeps running while nothing is dialled */
static void expect_parked(void)
{
	expect_line(TEST_BACKEND_PIPE_DLCI1, MODEM_CELLULAR_TEST_PERIODIC_CMD);
	ok(TEST_BACKEND_PIPE_DLCI1);
	expect_read(TEST_BACKEND_PIPE_DLCI1);
	expect_state(modem, TEST_BACKEND_STATE_CMUX);
}

/* Admit the interface and bring the link up. Registration outlives a hang-up, so a
 * re-dial goes straight to link up.
 */
static void dial(void)
{
	zassert_ok(net_if_up(ppp_iface()));
	expect_line(TEST_BACKEND_PIPE_DLCI2, MODEM_CELLULAR_TEST_DIAL_CMD);
	ok(TEST_BACKEND_PIPE_DLCI2);
	registered(TEST_BACKEND_PIPE_DLCI1);
	expect_state(modem, TEST_BACKEND_STATE_LINK_UP);
}

ZTEST(modem_cellular_on_demand, test_dial_on_admin_up)
{
	park();
	expect_parked();
	expect_parked();
	dial();
}

/* An interface admitted before the modem is up is dialled as soon as it is */
ZTEST(modem_cellular_on_demand, test_admin_up_before_parking)
{
	zassert_ok(net_if_up(ppp_iface()));
	park();
	expect_line(TEST_BACKEND_PIPE_DLCI2, MODEM_CELLULAR_TEST_DIAL_CMD);
}

/* Taking the interface down hangs up, returning to wait for the next admit */
ZTEST(modem_cellular_on_demand, test_hangup)
{
	park();
	dial();

	zassert_ok(net_if_down(ppp_iface()));
	expect_state(modem, TEST_BACKEND_STATE_CMUX);
	expect_parked();
	dial();
}

/* A hang-up while the dial script runs abandons it */
ZTEST(modem_cellular_on_demand, test_hangup_while_dialing)
{
	park();
	zassert_ok(net_if_up(ppp_iface()));
	expect_line(TEST_BACKEND_PIPE_DLCI2, MODEM_CELLULAR_TEST_DIAL_CMD);

	zassert_ok(net_if_down(ppp_iface()));
	expect_parked();
	dial();
}

/* An activation while parked counts as registration once the interface is admitted */
ZTEST(modem_cellular_on_demand, test_cgev_pdn_act_while_parked)
{
	park();
	test_backend_respond(TEST_BACKEND_PIPE_DLCI1, "+CGEV: ME PDN ACT 1\r");
	expect_read(TEST_BACKEND_PIPE_DLCI1);
	flush_driver_events();

	zassert_ok(net_if_up(ppp_iface()));
	expect_line(TEST_BACKEND_PIPE_DLCI2, MODEM_CELLULAR_TEST_DIAL_CMD);
	ok(TEST_BACKEND_PIPE_DLCI2);
	expect_state(modem, TEST_BACKEND_STATE_LINK_UP);
}

/* While parked, a ring reopens the UART the CMUX closed to save power */
ZTEST(modem_cellular_on_demand, test_ring)
{
	const struct gpio_dt_spec ring_gpio =
		GPIO_DT_SPEC_GET(DT_NODELABEL(modem_on_demand), mdm_ring_gpios);
	k_timepoint_t end;

	park();
	test_backend_cmux_power_save();
	zassert_false(test_backend_pipe_is_open(TEST_BACKEND_PIPE_UART), "UART still open");

	zassert_ok(gpio_emul_input_set_dt(&ring_gpio, 1));
	zassert_ok(gpio_emul_input_set_dt(&ring_gpio, 0));
	end = sys_timepoint_calc(K_SECONDS(2));
	while (!test_backend_pipe_is_open(TEST_BACKEND_PIPE_UART)) {
		zassert_false(sys_timepoint_expired(end), "ring did not reopen the UART");
		k_msleep(1);
	}
}

ZTEST(modem_cellular_on_demand, test_suspend)
{
	park();
	suspend_and_shutdown(modem);
}

/* A paused periodic script skips its runs, and runs at once when resumed */
ZTEST(modem_cellular_on_demand, test_periodic_pause)
{
	int64_t start;

	park();
	zassert_ok(cellular_modem_pause_periodic_script(modem));
	expect_no_line(K_MSEC(2 * CONFIG_MODEM_CELLULAR_PERIODIC_SCRIPT_MS));

	start = k_uptime_get();
	zassert_ok(cellular_modem_resume_periodic_script(modem));
	expect_line(TEST_BACKEND_PIPE_DLCI1, MODEM_CELLULAR_TEST_PERIODIC_CMD);
	zassert_true(k_uptime_delta(&start) < CONFIG_MODEM_CELLULAR_PERIODIC_SCRIPT_MS / 2,
		     "skipped run waited for the next interval");
	ok(TEST_BACKEND_PIPE_DLCI1);
	expect_read(TEST_BACKEND_PIPE_DLCI1);
	expect_state(modem, TEST_BACKEND_STATE_CMUX);
}

/* Without a skipped run, resuming leaves the periodic script on its interval */
ZTEST(modem_cellular_on_demand, test_periodic_resume_before_due)
{
	park();
	zassert_ok(cellular_modem_pause_periodic_script(modem));
	zassert_ok(cellular_modem_resume_periodic_script(modem));
	expect_no_line(K_MSEC(CONFIG_MODEM_CELLULAR_PERIODIC_SCRIPT_MS / 2));
	expect_parked();
}

/* The periodic script exhausting its failure budget restarts the modem */
ZTEST(modem_cellular_on_demand, test_periodic_failures)
{
	park();
	for (int i = 0; i < CONFIG_MODEM_CELLULAR_MAX_SCRIPT_FAILURES; i++) {
		expect_line(TEST_BACKEND_PIPE_DLCI1, MODEM_CELLULAR_TEST_PERIODIC_CMD);
		respond_error(TEST_BACKEND_PIPE_DLCI1);
	}
	expect_line(TEST_BACKEND_PIPE_UART, MODEM_CELLULAR_TEST_SET_BAUDRATE_CMD);
}

static void on_demand_after(void *fixture)
{
	/*
	 * Taken down while the carrier is still on: halting releases PPP, and the test peer never
	 * opens LCP, so without the carrier PPP L2 cannot complete the lower-down. The halt
	 * discards whatever the driver queues in response.
	 */
	if (net_if_is_admin_up(ppp_iface())) {
		zassert_ok(net_if_down(ppp_iface()));
	}

	modem_test_after(fixture);
}

ZTEST_SUITE(modem_cellular_on_demand, NULL, modem_test_setup, modem_test_before,
	    on_demand_after, NULL);
```
